# TLE987x register map
Vendor: Infineon; File version: 4.1
CPU: CM3 r0p0, little endian, no MPU, no FPU, 4 interrupt priority bits
Registers are 32-bit, read-write, reset 0x0 unless marked. A register's access mark holds for its fields unless they carry their own. Offsets are from the block's base; [hi:lo] are bit positions; 'fields as' and 'values as' point back to an identical list.

## SCUPM — System Control Unit for Power Modules
Base 0x50006000
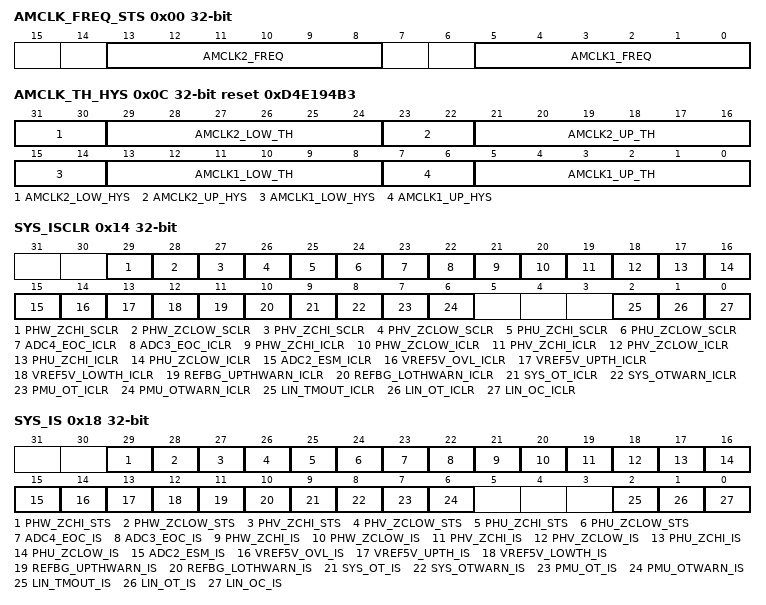
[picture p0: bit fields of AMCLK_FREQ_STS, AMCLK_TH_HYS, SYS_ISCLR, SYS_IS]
0x00 AMCLK_FREQ_STS ro (reset mask 0xC0C0) — Analog Module Clock Frequency Status Register
  [13:8] AMCLK2_FREQ — Current frequency of Analog Module Clock 2 (TFILT_CLK)
  [5:0] AMCLK1_FREQ — Current frequency of Analog Module Clock System Clock (MI_CLK)
0x04 AMCLK_CTRL reset 0x1 — Analog Module Clock Control
  [0] CLKWDT_PD_N — Clock Watchdog Powerdown
    0=DISABLE (Clock Watchdog disabled); 1=ENABLE (Clock Watchdog enabaled)
0x0C AMCLK_TH_HYS reset 0xD4E194B3 — Analog Module Clock Limit Register
  [31:30] AMCLK2_LOW_HYS — Analog Module Clock 2 (TFILT_CLK) Lower Hysteresis
  [29:24] AMCLK2_LOW_TH — Analog Module Clock 2 (TFILT_CLK) Lower Limit Threshold
  [23:22] AMCLK2_UP_HYS — Analog Module Clock 2 (TFILT_CLK) Upper Hysteresis
  [21:16] AMCLK2_UP_TH — Analog Module Clock 2 (TFILT_CLK) Upper Limit Threshold
  [15:14] AMCLK1_LOW_HYS — Analog Module Clock 1 (MI_CLK) Lower Hysteresis
  [13:8] AMCLK1_LOW_TH — Analog Module Clock 1 (MI_CLK) Lower Limit Threshold
  [7:6] AMCLK1_UP_HYS — Analog Module Clock 1 (MI_CLK) Upper Hysteresis
  [5:0] AMCLK1_UP_TH — Analog Module Clock 1 (MI_CLK) Upper Limit Threshold
0x14 SYS_ISCLR wo — System Interrupt Status Clear
  [29] PHW_ZCHI_SCLR — Phase W Zero Crossing Comperator High Status
    0=INACTIVE (no status set); 1=ACTIVE (at least one status set)
  [28] PHW_ZCLOW_SCLR — Phase W Zero Crossing Comperator Low Status
    values as PHW_ZCHI_SCLR
  [27] PHV_ZCHI_SCLR — Phase V Zero Crossing Comperator High Status
    values as PHW_ZCHI_SCLR
  [26] PHV_ZCLOW_SCLR — Phase V Zero Crossing Comperator Low Status
    values as PHW_ZCHI_SCLR
  [25] PHU_ZCHI_SCLR — Phase U Zero Crossing Comperator High Status
    values as PHW_ZCHI_SCLR
  [24] PHU_ZCLOW_SCLR — Phase U Zero Crossing Comperator Low Status
    values as PHW_ZCHI_SCLR
  [23] ADC4_EOC_ICLR — ADC4 EOC Interrupt Status
    0=INACTIVE (no interrupt status set); 1=ACTIVE (at least one interrupt status set)
  [22] ADC3_EOC_ICLR — ADC3 EOC Interrupt Status
    values as ADC4_EOC_ICLR
  [21] PHW_ZCHI_ICLR — Phase W Zero Crossing Comperator High Interrupt Status
    values as ADC4_EOC_ICLR
  [20] PHW_ZCLOW_ICLR — Phase W Zero Crossing Comperator Low Interrupt Status
    values as ADC4_EOC_ICLR
  [19] PHV_ZCHI_ICLR — Phase V Zero Crossing Comperator High Interrupt Status
    values as ADC4_EOC_ICLR
  [18] PHV_ZCLOW_ICLR — Phase V Zero Crossing Comperator Low Interrupt Status
    values as ADC4_EOC_ICLR
  [17] PHU_ZCHI_ICLR — Phase U Zero Crossing Comperator High Interrupt Status
    values as ADC4_EOC_ICLR
  [16] PHU_ZCLOW_ICLR — Phase U Zero Crossing Comperator Low Interrupt Status
    values as ADC4_EOC_ICLR
  [15] ADC2_ESM_ICLR — ADC2 Exceptional Sequence Measurement Interrupt Status
    values as ADC4_EOC_ICLR
  [14] VREF5V_OVL_ICLR — VREF5V Overload Interrupt Status
    values as ADC4_EOC_ICLR
  [13] VREF5V_UPTH_ICLR — VREF5V ADC1 Reference Overvoltage (ADC2, Channel 4) Interrupt Status
    values as ADC4_EOC_ICLR
  [12] VREF5V_LOWTH_ICLR — VREF5V ADC1 Reference Undervoltage (ADC2, Channel 4) Interrupt Status
    values as ADC4_EOC_ICLR
  [11] REFBG_UPTHWARN_ICLR — 8 Bit ADC2 Reference Overvoltage (ADC2, Channel 5) interrupt status
    values as ADC4_EOC_ICLR
  [10] REFBG_LOTHWARN_ICLR — 8 Bit ADC2 Reference Undervoltage (ADC2, Channel 5) interrupt status
    values as ADC4_EOC_ICLR
  [9] SYS_OT_ICLR — System Overtemperature Shutdown (ADC2, Channel 8) interrupt status
    values as ADC4_EOC_ICLR
  [8] SYS_OTWARN_ICLR — System Overtemperature Prewarning (ADC2, Channel 8) interrupt status
    values as ADC4_EOC_ICLR
  [7] PMU_OT_ICLR — PMU Regulator Overtemperature Shutdown (ADC2, Channel 9) interrupt status
    values as ADC4_EOC_ICLR
  [6] PMU_OTWARN_ICLR — PMU Regulator Overtemperature Prewarning (ADC2, Channel 9) interrupt status
    values as ADC4_EOC_ICLR
  [2] LIN_TMOUT_ICLR — LIN TXD timeout
    0=INACTIVE (no interrupt status set); 1=ACTIVE (LIN Overtemperature occurred)
  [1] LIN_OT_ICLR — LIN Overtemperature interrupt status
    values as LIN_TMOUT_ICLR
  [0] LIN_OC_ICLR — LIN Overcurrent interrupt status
    values as ADC4_EOC_ICLR
0x18 SYS_IS ro — System Interrupt Status
  [29] PHW_ZCHI_STS — Phase W Zero Crossing Comperator High Status
    values as SYS_ISCLR.PHW_ZCHI_SCLR
  [28] PHW_ZCLOW_STS — Phase W Zero Crossing Comperator Low Status
    values as SYS_ISCLR.PHW_ZCHI_SCLR
  [27] PHV_ZCHI_STS — Phase V Zero Crossing Comperator High Status
    values as SYS_ISCLR.PHW_ZCHI_SCLR
  [26] PHV_ZCLOW_STS — Phase V Zero Crossing Comperator Low Status
    values as SYS_ISCLR.PHW_ZCHI_SCLR
  [25] PHU_ZCHI_STS — Phase U Zero Crossing Comperator High Status
    values as SYS_ISCLR.PHW_ZCHI_SCLR
  [24] PHU_ZCLOW_STS — Phase U Zero Crossing Comperator Low Status
    values as SYS_ISCLR.PHW_ZCHI_SCLR
  [23] ADC4_EOC_IS — ADC4 EOC Interrupt Status
    values as SYS_ISCLR.ADC4_EOC_ICLR
  [22] ADC3_EOC_IS — ADC3 EOC Interrupt Status
    values as SYS_ISCLR.ADC4_EOC_ICLR
  [21] PHW_ZCHI_IS — Phase W Zero Crossing Comperator High Interrupt Status
    values as SYS_ISCLR.ADC4_EOC_ICLR
  [20] PHW_ZCLOW_IS — Phase W Zero Crossing Comperator Low Interrupt Status
    values as SYS_ISCLR.ADC4_EOC_ICLR
  [19] PHV_ZCHI_IS — Phase V Zero Crossing Comperator High Interrupt Status
    values as SYS_ISCLR.ADC4_EOC_ICLR
  [18] PHV_ZCLOW_IS — Phase V Zero Crossing Comperator Low Interrupt Status
    values as SYS_ISCLR.ADC4_EOC_ICLR
  [17] PHU_ZCHI_IS — Phase U Zero Crossing Comperator High Interrupt Status
    values as SYS_ISCLR.ADC4_EOC_ICLR
  [16] PHU_ZCLOW_IS — Phase U Zero Crossing Comperator Low Interrupt Status
    values as SYS_ISCLR.ADC4_EOC_ICLR
  [15] ADC2_ESM_IS — ADC2 Exceptional Sequence Measurement Interrupt Status
    values as SYS_ISCLR.ADC4_EOC_ICLR
  [14] VREF5V_OVL_IS — VREF5V Overload Interrupt Status
    values as SYS_ISCLR.ADC4_EOC_ICLR
  [13] VREF5V_UPTH_IS — VREF5V ADC1 Reference Overvoltage (ADC2, Channel 4) Interrupt Status
    values as SYS_ISCLR.ADC4_EOC_ICLR
  [12] VREF5V_LOWTH_IS — VREF5V ADC1 Reference Undervoltage (ADC2, Channel 4) Interrupt Status
    values as SYS_ISCLR.ADC4_EOC_ICLR
  [11] REFBG_UPTHWARN_IS — 8 Bit ADC2 Reference Overvoltage (ADC2, Channel 5) interrupt status
    values as SYS_ISCLR.ADC4_EOC_ICLR
  [10] REFBG_LOTHWARN_IS — 8 Bit ADC2 Reference Undervoltage (ADC2, Channel 5) interrupt status
    values as SYS_ISCLR.ADC4_EOC_ICLR
  [9] SYS_OT_IS — System Overtemperature Shutdown (ADC2, Channel 8) interrupt status
    values as SYS_ISCLR.ADC4_EOC_ICLR
  [8] SYS_OTWARN_IS — System Overtemperature Prewarning (ADC2, Channel 8) interrupt status
    values as SYS_ISCLR.ADC4_EOC_ICLR
  [7] PMU_OT_IS — PMU Regulator Overtemperature Shutdown (ADC2, Channel 9) interrupt status
    values as SYS_ISCLR.ADC4_EOC_ICLR
  [6] PMU_OTWARN_IS — PMU Regulator Overtemperature Prewarning (ADC2, Channel 9) interrupt status
    values as SYS_ISCLR.ADC4_EOC_ICLR
  [2] LIN_TMOUT_IS — LIN TXD timeout
    0=INACTIVE (no interrupt status set); 1=ACTIVE (LIN TXD timeout occurred)
  [1] LIN_OT_IS — LIN Overtemperature interrupt status
    values as SYS_ISCLR.LIN_TMOUT_ICLR
  [0] LIN_OC_IS — LIN Overcurrent interrupt status
    0=INACTIVE (no interrupt status set); 1=ACTIVE (LIN Overcurrent occurred)
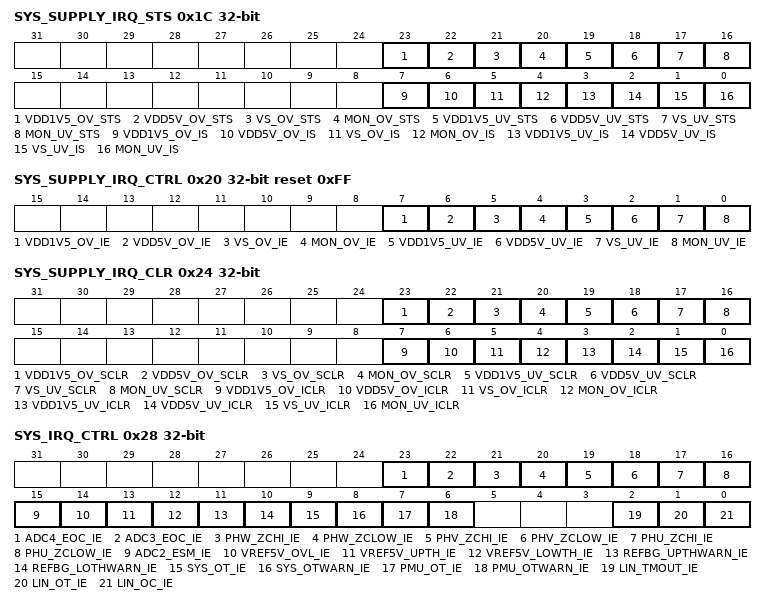
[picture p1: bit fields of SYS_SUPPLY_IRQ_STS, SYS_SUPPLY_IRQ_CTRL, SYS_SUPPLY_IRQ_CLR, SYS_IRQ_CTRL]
0x1C SYS_SUPPLY_IRQ_STS ro — System Supply Interrupt Status
  [23] VDD1V5_OV_STS — VDDC Overvoltage Status
    0=No_Overvoltage (occurred); 1=Overvoltage (occurred)
  [22] VDD5V_OV_STS — VDDP Overvoltage Status
    0=No_Overvoltage (occurred); 1=Overvoltage (occurred)
  [21] VS_OV_STS — VS Overvoltage Interrupt Status
    0=No_Overvoltage (occurred); 1=Overvoltage (occurred)
  [20] MON_OV_STS — MON Overvoltage Status
    0=No_Overvoltage (occurred); 1=Overvoltage (occurred)
  [19] VDD1V5_UV_STS — VDDC Undervoltage Status
    0=No_Undervoltage (occurred); 1=Undervoltage (occurred)
  [18] VDD5V_UV_STS — VDDP Undervoltage Status
    0=No_Undervoltage (occurred); 1=Undervoltage (occurred)
  [17] VS_UV_STS — VS Undervoltage Status
    0=No_Undervoltage (occurred); 1=Undervoltage (occurred)
  [16] MON_UV_STS — MON Undervoltage Status
    0=No_Undervoltage (occurred); 1=Undervoltage (occurred)
  [7] VDD1V5_OV_IS — VDDC Overvoltage Interrupt Status (ADC2 channel 3)
    0=No_Overvoltage_Interrupt (occurred); 1=Overvoltage_Interrupt (occurred)
  [6] VDD5V_OV_IS — VDDP Overvoltage Interrupt Status (ADC2 channel 2)
    values as VDD1V5_OV_IS
  [5] VS_OV_IS — VS Overvoltage Interrupt Status (ADC2 channel 1)
    values as VDD1V5_OV_IS
  [4] MON_OV_IS — MON Overvoltage Interrupt Status (ADC2 channel 4)
    values as VDD1V5_OV_IS
  [3] VDD1V5_UV_IS — VDDC Undervoltage Interrupt Status (ADC2 channel 3)
    0=No_Undervoltage_Interrupt (occurred); 1=Undervoltage_Interrupt (occurred)
  [2] VDD5V_UV_IS — VDDP Undervoltage Interrupt Status (ADC2 channel 2)
    values as VDD1V5_UV_IS
  [1] VS_UV_IS — VS Undervoltage Interrupt Status (ADC2 channel 1)
    values as VDD1V5_UV_IS
  [0] MON_UV_IS — MON Undervoltage Interrupt Status (ADC2 channel 4)
    values as VDD1V5_UV_IS
0x20 SYS_SUPPLY_IRQ_CTRL reset 0xFF — System Supply Interrupt Control
  [all] fields
    0=Interrupt is disabled; 1=Interrupt is enabled
  [7] VDD1V5_OV_IE — VDD1V5 Overvoltage Interrupt Enable
  [6] VDD5V_OV_IE — VDD5V Overvoltage Interrupt Enable
  [5] VS_OV_IE — VS Overvoltage Interrupt Enable
  [4] MON_OV_IE — MON Overvoltage Interrupt Enable
  [3] VDD1V5_UV_IE — VDD1V5 Undervoltage Interrupt Enable
  [2] VDD5V_UV_IE — VDD5V Undervoltage Interrupt Enable
  [1] VS_UV_IE — VS Undervoltage Interrupt Enable
  [0] MON_UV_IE — MON Undervoltage Interrupt Enable
0x24 SYS_SUPPLY_IRQ_CLR wo — System Supply Interrupt Status Clear
  [23] VDD1V5_OV_SCLR — VDDC Overvoltage Status
    0=No_Overvoltage (occurred); 1=Overvoltage (occurred)
  [22] VDD5V_OV_SCLR — VDDP Overvoltage Status
    0=No_Overvoltage (occurred); 1=Overvoltage (occurred)
  [21] VS_OV_SCLR — VS Overvoltage Interrupt Status
    0=No_Overvoltage (occurred); 1=Overvoltage (occurred)
  [20] MON_OV_SCLR — MON Overvoltage Status
    0=No_Overvoltage (occurred); 1=Overvoltage (occurred)
  [19] VDD1V5_UV_SCLR — VDDC Undervoltage Status
    0=No_Undervoltage (occurred); 1=Undervoltage (occurred)
  [18] VDD5V_UV_SCLR — VDDP Undervoltage Status
    0=No_Undervoltage (occurred); 1=Undervoltage (occurred)
  [17] VS_UV_SCLR — VS Undervoltage Status
    0=No_Undervoltage (occurred); 1=Undervoltage (occurred)
  [16] MON_UV_SCLR — MON Undervoltage Status
    0=No_Undervoltage (occurred); 1=Undervoltage (occurred)
  [7] VDD1V5_OV_ICLR — VDDC Overvoltage Interrupt Status (ADC2 channel 3)
    values as SYS_SUPPLY_IRQ_STS.VDD1V5_OV_IS
  [6] VDD5V_OV_ICLR — VDDP Overvoltage Interrupt Status (ADC2 channel 2)
    values as SYS_SUPPLY_IRQ_STS.VDD1V5_OV_IS
  [5] VS_OV_ICLR — VS Overvoltage Interrupt Status (ADC2 channel 1)
    values as SYS_SUPPLY_IRQ_STS.VDD1V5_OV_IS
  [4] MON_OV_ICLR — MON Overvoltage Interrupt Status (ADC2 channel 4)
    values as SYS_SUPPLY_IRQ_STS.VDD1V5_OV_IS
  [3] VDD1V5_UV_ICLR — VDDC Undervoltage Interrupt Status (ADC2 channel 3)
    values as SYS_SUPPLY_IRQ_STS.VDD1V5_UV_IS
  [2] VDD5V_UV_ICLR — VDDP Undervoltage Interrupt Status (ADC2 channel 2)
    values as SYS_SUPPLY_IRQ_STS.VDD1V5_UV_IS
  [1] VS_UV_ICLR — VS Undervoltage Interrupt Status (ADC2 channel 1)
    values as SYS_SUPPLY_IRQ_STS.VDD1V5_UV_IS
  [0] MON_UV_ICLR — MON Undervoltage Interrupt Status (ADC2 channel 4)
    values as SYS_SUPPLY_IRQ_STS.VDD1V5_UV_IS
0x28 SYS_IRQ_CTRL — System Interrupt Control
  [all] fields
    0=Interrupt is disabled; 1=Interrupt is enabled
  [23] ADC4_EOC_IE — ADC4 EOC Interrupt Enable
  [22] ADC3_EOC_IE — ADC3 EOC Interrupt Enable
  [21] PHW_ZCHI_IE — Phase W Zero Crossing Comperator High Interrupt Enable
  [20] PHW_ZCLOW_IE — Phase W Zero Crossing Comperator Low Interrupt Enable
  [19] PHV_ZCHI_IE — Phase V Zero Crossing Comperator High Interrupt Enable
  [18] PHV_ZCLOW_IE — Phase V Zero Crossing Comperator Low Interrupt Enable
  [17] PHU_ZCHI_IE — Phase U Zero Crossing Comperator High Interrupt Enable
  [16] PHU_ZCLOW_IE — Phase U Zero Crossing Comperator Low Interrupt Enable
  [15] ADC2_ESM_IE — ADC2 Exceptional Sequence Measurement Interrupt Enable
  [14] VREF5V_OVL_IE — VREF5V Overload Interrupt Enable
  [13] VREF5V_UPTH_IE — VREF5V ADC1 Reference Overvoltage (ADC2, Channel 4) Interrupt Enable
  [12] VREF5V_LOWTH_IE — VREF5V ADC1 Reference Undervoltage (ADC2, Channel 4) Interrupt Enable
  [11] REFBG_UPTHWARN_IE — Reference Voltage Overvoltage Interrupt Enable
  [10] REFBG_LOTHWARN_IE — Reference Voltage Undervoltage Interrupt Enable
  [9] SYS_OT_IE — System Overtemperature Shutdown Interrupt Enable (leads to shutdown of System)
  [8] SYS_OTWARN_IE — System Overtemperature Warning Interrupt Enable
  [7] PMU_OT_IE — PMU Regulator Overtemperature Shutdown Interrupt Enable (leads to shutdown of System)
  [6] PMU_OTWARN_IE — PMU Regulator Overtemperature Warning Interrupt Enable
  [2] LIN_TMOUT_IE — LIN TXD timeout Interrupt Enable
  [1] LIN_OT_IE — LIN Overtemperature Interrupt Enable
  [0] LIN_OC_IE — LIN Overcurrent Interrupt Enable
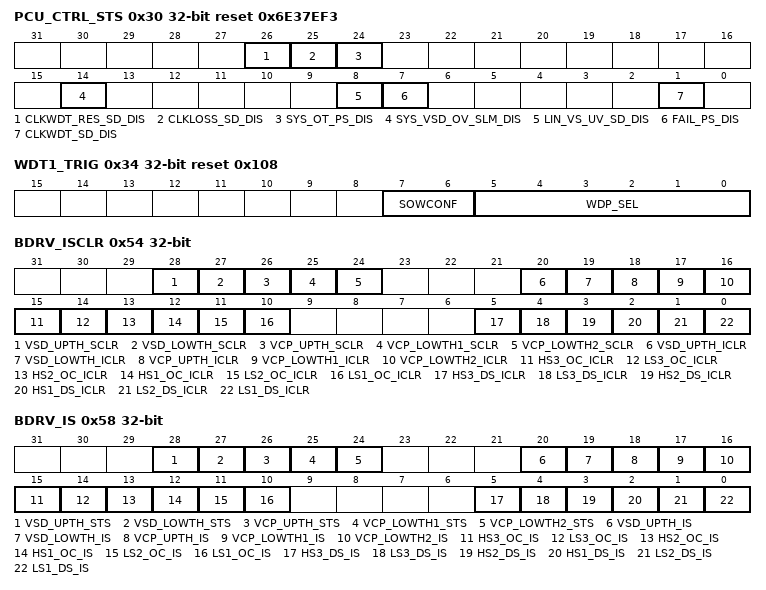
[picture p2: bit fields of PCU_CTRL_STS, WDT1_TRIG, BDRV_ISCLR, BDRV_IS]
0x30 PCU_CTRL_STS reset 0x6E37EF3 — Power Control Unit Control Status
  [26] CLKWDT_RES_SD_DIS — Clock Watchdog Reset Disable
    0=Enable (Clock Watchdog Reset Enable); 1=Disable (Clock Watchdog Reset Disable)
  [25] CLKLOSS_SD_DIS — Power Switches Loss of Clock Shutdown Disable (AMCLK3)
    0=Enable (Automatic Shutdown Signal for Power Switches in case of loss of clock); 1=Disable (Automatic Shutdown Signal for Power Switches in case of loss of clock)
  [24] SYS_OT_PS_DIS — System Overtemperature Power Switches Shutdown Disable
    0=Enable (Automatic Shutdown Signal for Power Switches in case of system overtemperature preenable); 1=Disable (Automatic Shutdown Signal for Power Switches in case of system overtemperature enable)
  [14] SYS_VSD_OV_SLM_DIS — VSD Overvoltage Shutdown for Peripherals Disable
    0=Enable (Automatic Shutdown for Power modules in case of VSD Overvoltage enabled); 1=Disable (Automatic Shutdown for Power modules in case of VSD Overvoltage disabled)
  [8] LIN_VS_UV_SD_DIS — LIN Module VS Undervoltage Transmitter Shutdown
    0=Enable (Automatic Shutdown for Power modules in case of VS Undervoltage enabled); 1=Disable (Automatic Shutdown for Power modules in case of VS Undervoltage disabled)
  [7] FAIL_PS_DIS — Disable LIN, BDRV and CP because of Overtemperature
    0=Switch_off_Enabled (LIN, BDRV and CP will be turned off when Overtemperature occurs); 1=Switch_off_Disabled (LIN, BDRV and CP will be kept on when Overtemperature occurs)
  [1] CLKWDT_SD_DIS — Power Modules Clock Watchdog Shutdown Disable
    0=Shutdown_Enable (Power Devices will be switched off when Clock Watchdog occurs); 1=Shutdown_Disable (Power Devices will not be shutdown when Clock Watchog occurs)
0x34 WDT1_TRIG reset 0x108 — WDT1 Watchdog Control
  [7:6] SOWCONF — Short Open Window Configuration
    0=DIS (Short Open Windows disabled); 1=SOW1 (one successive Short Open Window allowed); 2=SOW2 (two successive Short Open Windows allowed); 3=SOW3 (three successive Short Open Windows allowed)
  [5:0] WDP_SEL — Watchdog Period Selection and trigger
    0=SOW_TRIG (trigger short open window); 1=WP_1 (Watchdog period 16 ms); 2=WP_2 (Watchdog period 32 ms); 3=WP_3 (Watchdog period 48 ms); 63=WP_63 (Watchdog period 1008 ms)
0x54 BDRV_ISCLR wo — Bridge Driver Interrrupt Status Clear
  [28] VSD_UPTH_SCLR — Warning for VSD Upper Threshold Measurement (ADC2 channel 6) Status
    0=INACTIVE (no overvoltage status set); 1=ACTIVE (overvoltage status set)
  [27] VSD_LOWTH_SCLR — Warning for VSD Lower Threshold Measurement (ADC2 channel 6) Status
    0=INACTIVE (no undervoltage status set); 1=ACTIVE (undervoltage status set)
  [26] VCP_UPTH_SCLR — Warning for VCP Upper Threshold Measurement (ADC2 channel 7) Status
    values as VSD_UPTH_SCLR
  [25] VCP_LOWTH1_SCLR — Warning for VCP Lower Threshold 1 Measurement (ADC2 channel 7) Status
    values as VSD_LOWTH_SCLR
  [24] VCP_LOWTH2_SCLR — Warning for VCP Lower Threshold 2 Measurement (VCP_LOW Signal from CP) Status
    values as VSD_LOWTH_SCLR
  [20] VSD_UPTH_ICLR — Warning for VSD Upper Threshold Measurement (ADC2 channel 6) Interrupt Status
    0=INACTIVE (no interrupt status set); 1=ACTIVE (interrupt status set)
  [19] VSD_LOWTH_ICLR — Warning for VSD Lower Threshold Measurement (ADC2 channel 6) Interrupt Status
    values as VSD_UPTH_ICLR
  [18] VCP_UPTH_ICLR — Warning for VCP Upper Threshold Measurement (ADC2 channel 7) Interrupt Status
    values as VSD_UPTH_ICLR
  [17] VCP_LOWTH1_ICLR — Warning for VCP Lower Threshold 1 Measurement (ADC2 channel 7) Interrupt Status
    values as VSD_UPTH_ICLR
  [16] VCP_LOWTH2_ICLR — Warning for VCP Lower Threshold 2 Measurement (VCP_LOW Signal from CP) Interrupt Status
    values as VSD_UPTH_ICLR
  [15] HS3_OC_ICLR — External High Side 3 FET Over-current Status
    0=INACTIVE (no interrupt status set.); 1=ACTIVE (at least one interrupt status set.)
  [14] LS3_OC_ICLR — External Low Side 3 FET Over-current Status
    values as HS3_OC_ICLR
  [13] HS2_OC_ICLR — External High Side 2 FET Over-current Status
    values as HS3_OC_ICLR
  [12] HS1_OC_ICLR — External High 1 FET Over-current Status
    values as HS3_OC_ICLR
  [11] LS2_OC_ICLR — External Low Side 2 FET Over-current Status
    values as HS3_OC_ICLR
  [10] LS1_OC_ICLR — External Low Side 1 FET Over-current Status
    values as HS3_OC_ICLR
  [5] HS3_DS_ICLR — Bridge Driver High Side 3 Pre-Driver short Interrupt Status
    values as VSD_UPTH_ICLR
  [4] LS3_DS_ICLR — Bridge Driver Low Side 3 Pre-Driver short Interrupt Status
    values as VSD_UPTH_ICLR
  [3] HS2_DS_ICLR — Bridge Driver High Side 2 Pre-Driver short Interrupt Status
    values as VSD_UPTH_ICLR
  [2] HS1_DS_ICLR — Bridge Driver High Side 1 Pre-Driver short Interrupt Status
    values as VSD_UPTH_ICLR
  [1] LS2_DS_ICLR — Bridge Driver Low Side 2 Pre-Driver short Interrupt Status
    values as VSD_UPTH_ICLR
  [0] LS1_DS_ICLR — Bridge Driver Low Side 1 Pre-Driver short Interrupt Status
    values as VSD_UPTH_ICLR
0x58 BDRV_IS ro — Bridge Driver Interrrupt Status
  [28] VSD_UPTH_STS — Warning for VSD Upper Threshold Measurement (ADC2 channel 6) Status
    values as BDRV_ISCLR.VSD_UPTH_SCLR
  [27] VSD_LOWTH_STS — Warning for VSD Lower Threshold Measurement (ADC2 channel 6) Status
    values as BDRV_ISCLR.VSD_LOWTH_SCLR
  [26] VCP_UPTH_STS — Warning for VCP Upper Threshold Measurement (ADC2 channel 7) Status
    values as BDRV_ISCLR.VSD_UPTH_SCLR
  [25] VCP_LOWTH1_STS — Warning for VCP Lower Threshold 1 Measurement (ADC2 channel 7) Status
    values as BDRV_ISCLR.VSD_LOWTH_SCLR
  [24] VCP_LOWTH2_STS — Warning for VCP Lower Threshold 2 Measurement (VCP_LOW Signal from CP) Status
    values as BDRV_ISCLR.VSD_LOWTH_SCLR
  [20] VSD_UPTH_IS — Warning for VSD Upper Threshold Measurement (ADC2 channel 6) Interrupt Status
    values as BDRV_ISCLR.VSD_UPTH_ICLR
  [19] VSD_LOWTH_IS — Warning for VSD Lower Threshold Measurement (ADC2 channel 6) Interrupt Status
    values as BDRV_ISCLR.VSD_UPTH_ICLR
  [18] VCP_UPTH_IS — Warning for VCP Upper Threshold Measurement (ADC2 channel 7) Interrupt Status
    values as BDRV_ISCLR.VSD_UPTH_ICLR
  [17] VCP_LOWTH1_IS — Warning for VCP Lower Threshold 1 Measurement (ADC2 channel 7) Interrupt Status
    values as BDRV_ISCLR.VSD_UPTH_ICLR
  [16] VCP_LOWTH2_IS — Warning for VCP Lower Threshold 2 Measurement (VCP_LOW Signal from CP) Interrupt Status
    values as BDRV_ISCLR.VSD_UPTH_ICLR
  [15] HS3_OC_IS — External High Side 3 FET Over-current Status
    values as BDRV_ISCLR.HS3_OC_ICLR
  [14] LS3_OC_IS — External Low Side 3 FET Over-current Status
    values as BDRV_ISCLR.HS3_OC_ICLR
  [13] HS2_OC_IS — External High Side 2 FET Over-current Status
    values as BDRV_ISCLR.HS3_OC_ICLR
  [12] HS1_OC_IS — External High 1 FET Over-current Status
    values as BDRV_ISCLR.HS3_OC_ICLR
  [11] LS2_OC_IS — External Low Side 2 FET Over-current Status
    values as BDRV_ISCLR.HS3_OC_ICLR
  [10] LS1_OC_IS — External Low Side 1 FET Over-current Status
    values as BDRV_ISCLR.HS3_OC_ICLR
  [5] HS3_DS_IS — Bridge Driver High Side 3 Pre-Driver short Interrupt Status
    values as BDRV_ISCLR.VSD_UPTH_ICLR
  [4] LS3_DS_IS — Bridge Driver Low Side 3 Pre-Driver short Interrupt Status
    values as BDRV_ISCLR.VSD_UPTH_ICLR
  [3] HS2_DS_IS — Bridge Driver High Side 2 Pre-Driver short Interrupt Status
    values as BDRV_ISCLR.VSD_UPTH_ICLR
  [2] HS1_DS_IS — Bridge Driver High Side 1 Pre-Driver short Interrupt Status
    values as BDRV_ISCLR.VSD_UPTH_ICLR
  [1] LS2_DS_IS — Bridge Driver Low Side 2 Pre-Driver short Interrupt Status
    values as BDRV_ISCLR.VSD_UPTH_ICLR
  [0] LS1_DS_IS — Bridge Driver Low Side 1 Pre-Driver short Interrupt Status
    values as BDRV_ISCLR.VSD_UPTH_ICLR
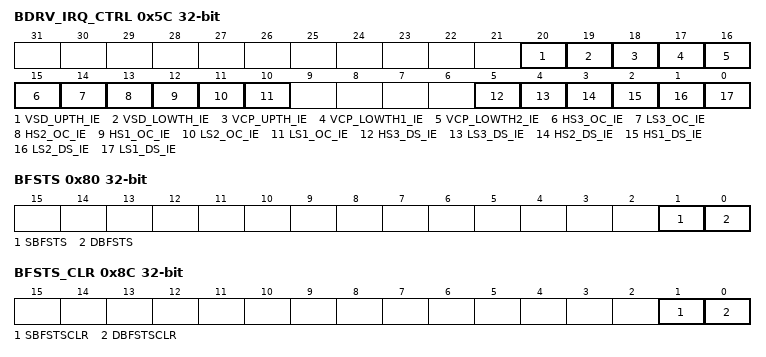
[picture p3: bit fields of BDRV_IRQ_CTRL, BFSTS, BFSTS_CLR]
0x5C BDRV_IRQ_CTRL — Bridge Driver Interrupt Control
  [all] fields
    0=Interrupt is disabled; 1=Interrupt is enabled
  [20] VSD_UPTH_IE — VSD Measurement Upper Threshold Interrupt Enable
  [19] VSD_LOWTH_IE — VSD Measurement Lower Threshold Interrupt Enable
  [18] VCP_UPTH_IE — VCP Measurement Upper Threshold Interrupt Enable
  [17] VCP_LOWTH1_IE — VCP Measurement Lower Threshold 1 Interrupt Enable
  [16] VCP_LOWTH2_IE — VCP Measurement Lower Threshold 2 Interrupt Enable
  [15] HS3_OC_IE — External High Side 3 FET Over-current Interrupt Enable
  [14] LS3_OC_IE — External Low Side 3 FET Over-current Interrupt Enable
  [13] HS2_OC_IE — External High Side 2 FET Over-current Interrupt Enable
  [12] HS1_OC_IE — External High Side 1 FET Over-current Interrupt Enable
  [11] LS2_OC_IE — External Low Side 2 FET Over-current Interrupt Enable
  [10] LS1_OC_IE — External Low Side 1 FET Over-current Interrupt Enable
  [5] HS3_DS_IE — Bridge Driver High Side 3 Pre-Driver Short Interrupt Enable
  [4] LS3_DS_IE — Bridge Driver Low Side 3 Pre-Driver Short Interrupt Enable
  [3] HS2_DS_IE — Bridge Driver High Side 2 Pre-Driver Short Interrupt Enable
  [2] HS1_DS_IE — Bridge Driver High Side 1 Pre-Driver Short Interrupt Enable
  [1] LS2_DS_IE — Bridge Driver Low Side 2 Pre-Driver Short Interrupt Enable
  [0] LS1_DS_IE — Bridge Driver Low Side 1 Pre-Driver Short Interrupt Enable
0x6C STCALIB — System Tick Calibration Register
  [25:0] STCALIB — System Tick Calibration
0x80 BFSTS ro — Bus Fault Status
  [1] SBFSTS — System Bus Fault Status Valid Flag
    1=Valid (Adress is valid); 0=not_valid (Adress is not valid)
  [0] DBFSTS — Data Bus Fault Status Valid Flag
    1=Valid (Adress is valid); 0=not_valid (Adress is not valid)
0x84 DBFA ro reset not defined — Data Bus Fault Address Register
0x88 SBFA ro reset not defined — System Bus Fault Address Register
0x8C BFSTS_CLR wo — Bus Fault Status Clear Register
  [1] SBFSTSCLR — System Bus Fault Status Clear Flag
    1=Cleared (Valid Adress is cleared); 0=not_cleared (Valid Adress is not cleared)
  [0] DBFSTSCLR — Data Bus Fault Status Clear Flag
    1=Cleared (Adress is cleared); 0=not_cleared (Adress is not cleared)
